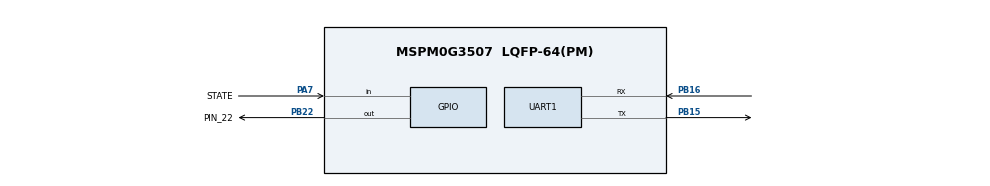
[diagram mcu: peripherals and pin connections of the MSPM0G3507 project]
/**
 * These arguments were used when this file was generated. They will be automatically applied on subsequent loads
 * via the GUI or CLI. Run CLI with '--help' for additional information on how to override these arguments.
 * @cliArgs --device "MSPM0G350X" --part "Default" --package "LQFP-64(PM)" --product "mspm0_sdk@2.10.00.04"
 * @v2CliArgs --device "MSPM0G3507" --package "LQFP-64(PM)" --product "mspm0_sdk@2.10.00.04"
 * @versions {"tool":"1.26.2+4477"}
 */

/**
 * Import the modules used in this configuration.
 */
const GPIO   = scripting.addModule("/ti/driverlib/GPIO", {}, false);
const GPIO1  = GPIO.addInstance();
const GPIO2  = GPIO.addInstance();
const GPIO3  = GPIO.addInstance();
const SYSCTL = scripting.addModule("/ti/driverlib/SYSCTL");
const UART   = scripting.addModule("/ti/driverlib/UART", {}, false);
const UART1  = UART.addInstance();

/**
 * Write custom configuration values to the imported modules.
 */
GPIO1.$name                              = "LED1";
GPIO1.port                               = "PORTB";
GPIO1.associatedPins[0].$name            = "PIN_22";
GPIO1.associatedPins[0].internalResistor = "PULL_DOWN";
GPIO1.associatedPins[0].assignedPin      = "22";
GPIO1.associatedPins[0].pin.$assign      = "PB22";

const Board = scripting.addModule("/ti/driverlib/Board", {}, false);

GPIO2.$name                   = "GPIO_GRP_0";
GPIO2.associatedPins[0].$name = "PIN_0";

GPIO3.$name                         = "HC05";
GPIO3.port                          = "PORTA";
GPIO3.associatedPins[0].$name       = "STATE";
GPIO3.associatedPins[0].direction   = "INPUT";
GPIO3.associatedPins[0].assignedPin = "7";
GPIO3.associatedPins[0].pin.$assign = "PA7";

SYSCTL.forceDefaultClkConfig = true;

UART1.$name                            = "UART_2";
UART1.rxFifoThreshold                  = "DL_UART_RX_FIFO_LEVEL_ONE_ENTRY";
UART1.enableDMARX                      = false;
UART1.enableDMATX                      = false;
UART1.uartClkSrc                       = "BUSCLK";
UART1.uartClkDiv                       = "4";
UART1.enableFIFO                       = true;
UART1.ovsRate                          = "16";
UART1.enabledInterrupts                = ["RX"];
UART1.peripheral.$assign               = "UART2";
UART1.peripheral.rxPin.$assign         = "PB16";
UART1.peripheral.txPin.$assign         = "PB15";
UART1.txPinConfig.$name                = "ti_driverlib_gpio_GPIOPinGeneric0";
UART1.txPinConfig.direction            = scripting.forceWrite("OUTPUT");
UART1.txPinConfig.hideOutputInversion  = scripting.forceWrite(false);
UART1.txPinConfig.onlyInternalResistor = scripting.forceWrite(false);
UART1.txPinConfig.passedPeripheralType = scripting.forceWrite("Digital");
UART1.rxPinConfig.$name                = "ti_driverlib_gpio_GPIOPinGeneric1";
UART1.rxPinConfig.hideOutputInversion  = scripting.forceWrite(false);
UART1.rxPinConfig.onlyInternalResistor = scripting.forceWrite(false);
UART1.rxPinConfig.passedPeripheralType = scripting.forceWrite("Digital");

/**
 * Pinmux solution for unlocked pins/peripherals. This ensures that minor changes to the automatic solver in a future
 * version of the tool will not impact the pinmux you originally saw.  These lines can be completely deleted in order to
 * re-solve from scratch.
 */
Board.peripheral.$suggestSolution            = "DEBUGSS";
Board.peripheral.swclkPin.$suggestSolution   = "PA20";
Board.peripheral.swdioPin.$suggestSolution   = "PA19";
GPIO2.associatedPins[0].pin.$suggestSolution = "PB13";
SYSCTL.peripheral.$suggestSolution           = "SYSCTL";
